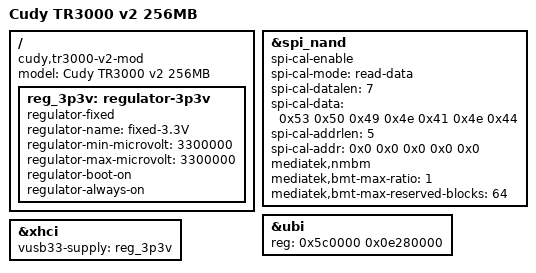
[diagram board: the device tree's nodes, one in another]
// SPDX-License-Identifier: (GPL-2.0 OR MIT)

/dts-v1/;

#include "mt7981b-cudy-tr3000-v1.dtsi"

/ {
	model = "Cudy TR3000 v2 256MB";
	compatible = "cudy,tr3000-v2-mod", "mediatek,mt7981";

	reg_3p3v: regulator-3p3v {
		compatible = "regulator-fixed";
		regulator-name = "fixed-3.3V";
		regulator-min-microvolt = <3300000>;
		regulator-max-microvolt = <3300000>;
		regulator-boot-on;
		regulator-always-on;
	};
};

&spi_nand {
	spi-cal-enable;
	spi-cal-mode = "read-data";
	spi-cal-datalen = <7>;
	spi-cal-data = /bits/ 8 <0x53 0x50 0x49 0x4e 0x41 0x4e 0x44>;
	spi-cal-addrlen = <5>;
	spi-cal-addr = /bits/ 32 <0x0 0x0 0x0 0x0 0x0>;

	mediatek,nmbm;
	mediatek,bmt-max-ratio = <1>;
	mediatek,bmt-max-reserved-blocks = <64>;
};

&ubi {
	reg = <0x5c0000 0x0e280000>;
};

&xhci {
	vusb33-supply = <&reg_3p3v>;
};
